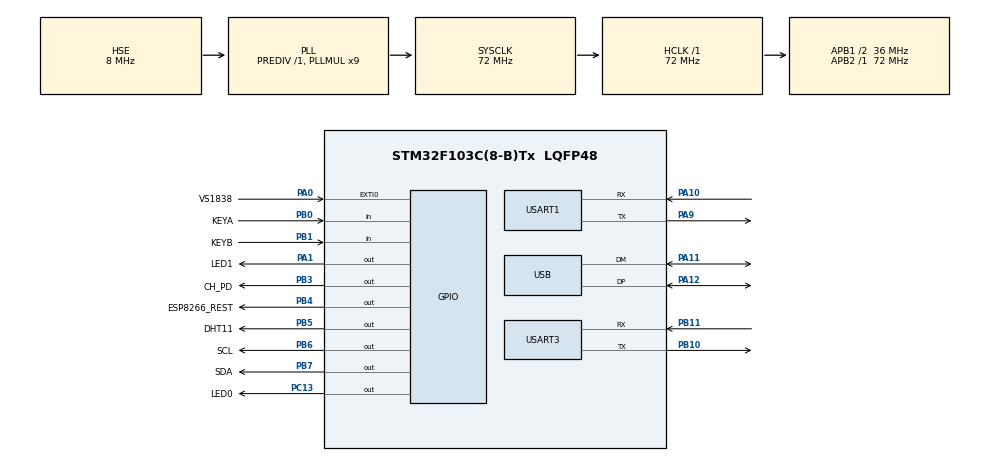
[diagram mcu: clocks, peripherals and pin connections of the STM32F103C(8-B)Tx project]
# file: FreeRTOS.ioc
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Dma.Request0=USART1_RX
Dma.Request1=USART1_TX
Dma.Request2=USART3_RX
Dma.Request3=USART3_TX
Dma.USART1_RX.0.Direction=DMA_PERIPH_TO_MEMORY
Dma.USART1_RX.0.Instance=DMA1_Channel5
Dma.USART1_RX.0.MemDataAlignment=DMA_MDATAALIGN_BYTE
Dma.USART1_RX.0.MemInc=DMA_MINC_ENABLE
Dma.USART1_RX.0.Mode=DMA_NORMAL
Dma.USART1_RX.0.PeriphDataAlignment=DMA_PDATAALIGN_BYTE
Dma.USART1_RX.0.PeriphInc=DMA_PINC_DISABLE
Dma.USART1_RX.0.Priority=DMA_PRIORITY_MEDIUM
Dma.USART1_TX.1.Direction=DMA_MEMORY_TO_PERIPH
Dma.USART1_TX.1.Instance=DMA1_Channel4
Dma.USART1_TX.1.MemDataAlignment=DMA_MDATAALIGN_BYTE
Dma.USART1_TX.1.MemInc=DMA_MINC_ENABLE
Dma.USART1_TX.1.Mode=DMA_NORMAL
Dma.USART1_TX.1.PeriphDataAlignment=DMA_PDATAALIGN_BYTE
Dma.USART1_TX.1.PeriphInc=DMA_PINC_DISABLE
Dma.USART1_TX.1.Priority=DMA_PRIORITY_MEDIUM
Dma.USART3_RX.2.Direction=DMA_PERIPH_TO_MEMORY
Dma.USART3_RX.2.Instance=DMA1_Channel3
Dma.USART3_RX.2.MemDataAlignment=DMA_MDATAALIGN_BYTE
Dma.USART3_RX.2.MemInc=DMA_MINC_ENABLE
Dma.USART3_RX.2.Mode=DMA_NORMAL
Dma.USART3_RX.2.PeriphDataAlignment=DMA_PDATAALIGN_BYTE
Dma.USART3_RX.2.PeriphInc=DMA_PINC_DISABLE
Dma.USART3_RX.2.Priority=DMA_PRIORITY_MEDIUM
Dma.USART3_TX.3.Direction=DMA_MEMORY_TO_PERIPH
Dma.USART3_TX.3.Instance=DMA1_Channel2
Dma.USART3_TX.3.MemDataAlignment=DMA_MDATAALIGN_BYTE
Dma.USART3_TX.3.MemInc=DMA_MINC_ENABLE
Dma.USART3_TX.3.Mode=DMA_NORMAL
Dma.USART3_TX.3.PeriphDataAlignment=DMA_PDATAALIGN_BYTE
Dma.USART3_TX.3.PeriphInc=DMA_PINC_DISABLE
Dma.USART3_TX.3.Priority=DMA_PRIORITY_MEDIUM
FREERTOS.Tasks01=ALL_init,0,128,StartInitTask,Default,NULL,Dynamic,NULL,NULL
Mcu.Family=STM32F1
Mcu.Name=STM32F103C(8-B)Tx
Mcu.Package=LQFP48
NVIC.DMA1_Channel2_IRQn=true\:5\:0\:false\:false\:true\:true\:false
NVIC.DMA1_Channel3_IRQn=true\:5\:0\:false\:false\:true\:true\:false
NVIC.DMA1_Channel4_IRQn=true\:5\:0\:false\:false\:true\:true\:false
NVIC.DMA1_Channel5_IRQn=true\:5\:0\:false\:false\:true\:true\:false
NVIC.PriorityGroup=NVIC_PRIORITYGROUP_4
NVIC.TIM1_UP_IRQn=true\:0\:0\:false\:false\:true\:false\:false
NVIC.TimeBase=TIM1_UP_IRQn
NVIC.TimeBaseIP=TIM1
NVIC.USART1_IRQn=true\:5\:0\:false\:false\:true\:true\:true
NVIC.USART3_IRQn=true\:5\:0\:false\:false\:true\:true\:true
PA0-WKUP.GPIO_Label=VS1838
PA0-WKUP.GPIO_ModeDefaultEXTI=GPIO_MODE_IT_FALLING
PA0-WKUP.Signal=GPXTI0
PA1.GPIO_Label=LED1
PA1.GPIO_PuPd=GPIO_PULLUP
PA1.GPIO_Speed=GPIO_SPEED_FREQ_HIGH
PA1.PinState=GPIO_PIN_SET
PA1.Signal=GPIO_Output
PA10.Mode=Asynchronous
PA10.Signal=USART1_RX
PA11.Mode=Device
PA11.Signal=USB_DM
PA12.Mode=Device
PA12.Signal=USB_DP
PA13.Mode=Serial_Wire
PA13.Signal=SYS_JTMS-SWDIO
PA14.Mode=Serial_Wire
PA14.Signal=SYS_JTCK-SWCLK
PA9.Mode=Asynchronous
PA9.Signal=USART1_TX
PB0.GPIO_Label=KEYA
PB0.GPIO_PuPd=GPIO_PULLUP
PB0.Signal=GPIO_Input
PB1.GPIO_Label=KEYB
PB1.GPIO_PuPd=GPIO_PULLUP
PB1.Signal=GPIO_Input
PB10.Mode=Asynchronous
PB10.Signal=USART3_TX
PB11.Mode=Asynchronous
PB11.Signal=USART3_RX
PB3.GPIO_Label=CH_PD
PB3.GPIO_ModeDefaultOutputPP=GPIO_MODE_OUTPUT_PP
PB3.GPIO_PuPd=GPIO_PULLUP
PB3.PinState=GPIO_PIN_SET
PB3.Signal=GPIO_Output
PB4.GPIO_Label=ESP8266_REST
PB4.GPIO_ModeDefaultOutputPP=GPIO_MODE_OUTPUT_PP
PB4.GPIO_PuPd=GPIO_PULLUP
PB4.GPIO_Speed=GPIO_SPEED_FREQ_LOW
PB4.PinState=GPIO_PIN_SET
PB4.Signal=GPIO_Output
PB5.GPIO_Label=DHT11
PB5.GPIO_ModeDefaultOutputPP=GPIO_MODE_OUTPUT_PP
PB5.GPIO_PuPd=GPIO_PULLUP
PB5.GPIO_Speed=GPIO_SPEED_FREQ_HIGH
PB5.PinState=GPIO_PIN_SET
PB5.Signal=GPIO_Output
PB6.GPIO_Label=SCL
PB6.GPIO_PuPd=GPIO_PULLUP
PB6.GPIO_Speed=GPIO_SPEED_FREQ_HIGH
PB6.PinState=GPIO_PIN_SET
PB6.Signal=GPIO_Output
PB7.GPIO_Label=SDA
PB7.GPIO_ModeDefaultOutputPP=GPIO_MODE_OUTPUT_PP
PB7.GPIO_PuPd=GPIO_PULLUP
PB7.GPIO_Speed=GPIO_SPEED_FREQ_HIGH
PB7.PinState=GPIO_PIN_SET
PB7.Signal=GPIO_Output
PC13-TAMPER-RTC.GPIO_Label=LED0
PC13-TAMPER-RTC.GPIO_PuPd=GPIO_PULLUP
PC13-TAMPER-RTC.GPIO_Speed=GPIO_SPEED_FREQ_HIGH
PC13-TAMPER-RTC.PinState=GPIO_PIN_SET
PC13-TAMPER-RTC.Signal=GPIO_Output
PD0-OSC_IN.Mode=HSE-External-Oscillator
PD0-OSC_IN.Signal=RCC_OSC_IN
PD1-OSC_OUT.Mode=HSE-External-Oscillator
PD1-OSC_OUT.Signal=RCC_OSC_OUT
ProjectManager.HeapSize=0x200
ProjectManager.StackSize=0x400
ProjectManager.TargetToolchain=MDK-ARM V5
RCC.AHBFreq_Value=72000000
RCC.APB1CLKDivider=RCC_HCLK_DIV2
RCC.APB1Freq_Value=36000000
RCC.APB1TimFreq_Value=72000000
RCC.APB2Freq_Value=72000000
RCC.APB2TimFreq_Value=72000000
RCC.HCLKFreq_Value=72000000
RCC.PLLMUL=RCC_PLL_MUL9
RCC.SYSCLKFreq_VALUE=72000000
RCC.SYSCLKSource=RCC_SYSCLKSOURCE_PLLCLK
RCC.USBFreq_Value=48000000
RCC.USBPrescaler=RCC_USBCLKSOURCE_PLL_DIV1_5
USART1.VirtualMode=VM_ASYNC
USART3.VirtualMode=VM_ASYNC
VP_FREERTOS_VS_ENABLE.Mode=Enabled
VP_SYS_VS_tim1.Mode=TIM1
board=custom

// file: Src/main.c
/**
  ******************************************************************************
  * @file           : main.c
  * @brief          : Main program body
  ******************************************************************************
  * This notice applies to any and all portions of this file
  * that are not between comment pairs USER CODE BEGIN and
  * USER CODE END. Other portions of this file, whether
  * inserted by the user or by software development tools
  * are owned by their respective copyright owners.
  *
  * Copyright (c) 2019 STMicroelectronics International N.V.
  * All rights reserved.
  *
  * Redistribution and use in source and binary forms, with or without
  * modification, are permitted, provided that the following conditions are met:
  *
  * 1. Redistribution of source code must retain the above copyright notice,
  *    this list of conditions and the following disclaimer.
  * 2. Redistributions in binary form must reproduce the above copyright notice,
  *    this list of conditions and the following disclaimer in the documentation
  *    and/or other materials provided with the distribution.
  * 3. Neither the name of STMicroelectronics nor the names of other
  *    contributors to this software may be used to endorse or promote products
  *    derived from this software without specific written permission.
  * 4. This software, including modifications and/or derivative works of this
  *    software, must execute solely and exclusively on microcontroller or
  *    microprocessor devices manufactured by or for STMicroelectronics.
  * 5. Redistribution and use of this software other than as permitted under
  *    this license is void and will automatically terminate your rights under
  *    this license.
  *
  * THIS SOFTWARE IS PROVIDED BY STMICROELECTRONICS AND CONTRIBUTORS "AS IS"
  * AND ANY EXPRESS, IMPLIED OR STATUTORY WARRANTIES, INCLUDING, BUT NOT
  * LIMITED TO, THE IMPLIED WARRANTIES OF MERCHANTABILITY, FITNESS FOR A
  * PARTICULAR PURPOSE AND NON-INFRINGEMENT OF THIRD PARTY INTELLECTUAL PROPERTY
  * RIGHTS ARE DISCLAIMED TO THE FULLEST EXTENT PERMITTED BY LAW. IN NO EVENT
  * SHALL STMICROELECTRONICS OR CONTRIBUTORS BE LIABLE FOR ANY DIRECT, INDIRECT,
  * INCIDENTAL, SPECIAL, EXEMPLARY, OR CONSEQUENTIAL DAMAGES (INCLUDING, BUT NOT
  * LIMITED TO, PROCUREMENT OF SUBSTITUTE GOODS OR SERVICES; LOSS OF USE, DATA,
  * OR PROFITS; OR BUSINESS INTERRUPTION) HOWEVER CAUSED AND ON ANY THEORY OF
  * LIABILITY, WHETHER IN CONTRACT, STRICT LIABILITY, OR TORT (INCLUDING
  * NEGLIGENCE OR OTHERWISE) ARISING IN ANY WAY OUT OF THE USE OF THIS SOFTWARE,
  * EVEN IF ADVISED OF THE POSSIBILITY OF SUCH DAMAGE.
  *
  ******************************************************************************
  */
#include "main.h"
#include "stm32f1xx_hal.h"
#include "cmsis_os.h"
#include "dma.h"
#include "usart.h"
#include "usb.h"
#include "gpio.h"

/* USER CODE BEGIN Includes */
#include "app.h"
/* USER CODE END Includes */

/* USER CODE BEGIN PV */
/* Private variables ---------------------------------------------------------*/

/* USER CODE END PV */

void SystemClock_Config(void);
void MX_FREERTOS_Init(void);

/* USER CODE BEGIN PFP */
/* Private function prototypes -----------------------------------------------*/

/* USER CODE END PFP */

int main(void)
{

  /* MCU Configuration----------------------------------------------------------*/

  /* Reset of all peripherals, Initializes the Flash interface and the Systick. */
  HAL_Init();

  /* Configure the system clock */
  SystemClock_Config();

  /* Initialize all configured peripherals */
  MX_GPIO_Init();
  MX_DMA_Init();
  MX_USART1_UART_Init();
  MX_USART3_UART_Init();
  MX_USB_PCD_Init();
  /* USER CODE BEGIN 2 */
	FirstInit();
  /* USER CODE END 2 */

  /* Call init function for freertos objects (in freertos.c) */
  MX_FREERTOS_Init();

  /* Start scheduler */
  osKernelStart();

  /* We should never get here as control is now taken by the scheduler */

  /* Infinite loop */
  while (1)
  {

  }

}

void SystemClock_Config(void)
{

  RCC_OscInitTypeDef RCC_OscInitStruct;
  RCC_ClkInitTypeDef RCC_ClkInitStruct;
  RCC_PeriphCLKInitTypeDef PeriphClkInit;

    /**Initializes the CPU, AHB and APB busses clocks
    */
  RCC_OscInitStruct.OscillatorType = RCC_OSCILLATORTYPE_HSE;
  RCC_OscInitStruct.HSEState = RCC_HSE_ON;
  RCC_OscInitStruct.HSEPredivValue = RCC_HSE_PREDIV_DIV1;
  RCC_OscInitStruct.HSIState = RCC_HSI_ON;
  RCC_OscInitStruct.PLL.PLLState = RCC_PLL_ON;
  RCC_OscInitStruct.PLL.PLLSource = RCC_PLLSOURCE_HSE;
  RCC_OscInitStruct.PLL.PLLMUL = RCC_PLL_MUL9;
  if (HAL_RCC_OscConfig(&RCC_OscInitStruct) != HAL_OK)
  {
    _Error_Handler(__FILE__, __LINE__);
  }

    /**Initializes the CPU, AHB and APB busses clocks
    */
  RCC_ClkInitStruct.ClockType = RCC_CLOCKTYPE_HCLK|RCC_CLOCKTYPE_SYSCLK
                              |RCC_CLOCKTYPE_PCLK1|RCC_CLOCKTYPE_PCLK2;
  RCC_ClkInitStruct.SYSCLKSource = RCC_SYSCLKSOURCE_PLLCLK;
  RCC_ClkInitStruct.AHBCLKDivider = RCC_SYSCLK_DIV1;
  RCC_ClkInitStruct.APB1CLKDivider = RCC_HCLK_DIV2;
  RCC_ClkInitStruct.APB2CLKDivider = RCC_HCLK_DIV1;

  if (HAL_RCC_ClockConfig(&RCC_ClkInitStruct, FLASH_LATENCY_2) != HAL_OK)
  {
    _Error_Handler(__FILE__, __LINE__);
  }

  PeriphClkInit.PeriphClockSelection = RCC_PERIPHCLK_USB;
  PeriphClkInit.UsbClockSelection = RCC_USBCLKSOURCE_PLL_DIV1_5;
  if (HAL_RCCEx_PeriphCLKConfig(&PeriphClkInit) != HAL_OK)
  {
    _Error_Handler(__FILE__, __LINE__);
  }

    /**Configure the Systick interrupt time
    */
  HAL_SYSTICK_Config(HAL_RCC_GetHCLKFreq()/1000);

    /**Configure the Systick
    */
  HAL_SYSTICK_CLKSourceConfig(SYSTICK_CLKSOURCE_HCLK);

  /* SysTick_IRQn interrupt configuration */
  HAL_NVIC_SetPriority(SysTick_IRQn, 15, 0);
}

void HAL_TIM_PeriodElapsedCallback(TIM_HandleTypeDef *htim)
{
  if (htim->Instance == TIM1) {
    HAL_IncTick();
  }
}

void _Error_Handler(char *file, int line)
{
  while(1)
  {
  }
}

/************************ (C) COPYRIGHT STMicroelectronics *****END OF FILE****/

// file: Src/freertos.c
/**
  ******************************************************************************
  * File Name          : freertos.c
  * Description        : Code for freertos applications
  ******************************************************************************
  * This notice applies to any and all portions of this file
  * that are not between comment pairs USER CODE BEGIN and
  * USER CODE END. Other portions of this file, whether
  * inserted by the user or by software development tools
  * are owned by their respective copyright owners.
  *
  * Copyright (c) 2019 STMicroelectronics International N.V.
  * All rights reserved.
  *
  * Redistribution and use in source and binary forms, with or without
  * modification, are permitted, provided that the following conditions are met:
  *
  * 1. Redistribution of source code must retain the above copyright notice,
  *    this list of conditions and the following disclaimer.
  * 2. Redistributions in binary form must reproduce the above copyright notice,
  *    this list of conditions and the following disclaimer in the documentation
  *    and/or other materials provided with the distribution.
  * 3. Neither the name of STMicroelectronics nor the names of other
  *    contributors to this software may be used to endorse or promote products
  *    derived from this software without specific written permission.
  * 4. This software, including modifications and/or derivative works of this
  *    software, must execute solely and exclusively on microcontroller or
  *    microprocessor devices manufactured by or for STMicroelectronics.
  * 5. Redistribution and use of this software other than as permitted under
  *    this license is void and will automatically terminate your rights under
  *    this license.
  *
  * THIS SOFTWARE IS PROVIDED BY STMICROELECTRONICS AND CONTRIBUTORS "AS IS"
  * AND ANY EXPRESS, IMPLIED OR STATUTORY WARRANTIES, INCLUDING, BUT NOT
  * LIMITED TO, THE IMPLIED WARRANTIES OF MERCHANTABILITY, FITNESS FOR A
  * PARTICULAR PURPOSE AND NON-INFRINGEMENT OF THIRD PARTY INTELLECTUAL PROPERTY
  * RIGHTS ARE DISCLAIMED TO THE FULLEST EXTENT PERMITTED BY LAW. IN NO EVENT
  * SHALL STMICROELECTRONICS OR CONTRIBUTORS BE LIABLE FOR ANY DIRECT, INDIRECT,
  * INCIDENTAL, SPECIAL, EXEMPLARY, OR CONSEQUENTIAL DAMAGES (INCLUDING, BUT NOT
  * LIMITED TO, PROCUREMENT OF SUBSTITUTE GOODS OR SERVICES; LOSS OF USE, DATA,
  * OR PROFITS; OR BUSINESS INTERRUPTION) HOWEVER CAUSED AND ON ANY THEORY OF
  * LIABILITY, WHETHER IN CONTRACT, STRICT LIABILITY, OR TORT (INCLUDING
  * NEGLIGENCE OR OTHERWISE) ARISING IN ANY WAY OUT OF THE USE OF THIS SOFTWARE,
  * EVEN IF ADVISED OF THE POSSIBILITY OF SUCH DAMAGE.
  *
  ******************************************************************************
  */

#include "FreeRTOS.h"
#include "task.h"
#include "cmsis_os.h"

/* USER CODE BEGIN Includes */
#include "app.h"
#include "GPIO.h"
#include "string.h"
#include "dma.h"
#include "main.h"
#include "stm32f1xx_hal.h"
#include "usart.h"
/* USER CODE END Includes */

osThreadId ALL_initHandle;

void StartInitTask(void const * argument);

void MX_FREERTOS_Init(void); /* (MISRA C 2004 rule 8.1) */

/* USER CODE BEGIN FunctionPrototypes */
//void vTask1(void const * argument);
/* USER CODE END FunctionPrototypes */

/* Hook prototypes */

/* Init FreeRTOS */

void MX_FREERTOS_Init(void) {

  /* Create the thread(s) */
  /* definition and creation of ALL_init */
  osThreadDef(ALL_init, StartInitTask, osPriorityNormal, 0, 128);
  ALL_initHandle = osThreadCreate(osThread(ALL_init), NULL);

}

/* StartInitTask function */
void StartInitTask(void const * argument)
{

  /* USER CODE BEGIN StartInitTask */
  /* Infinite loop */

	vTaskInit();
  for(;;)
  {
		HAL_GPIO_TogglePin(LED0_GPIO_Port,LED0_Pin);
  }
  /* USER CODE END StartInitTask */
}

/************************ (C) COPYRIGHT STMicroelectronics *****END OF FILE****/
